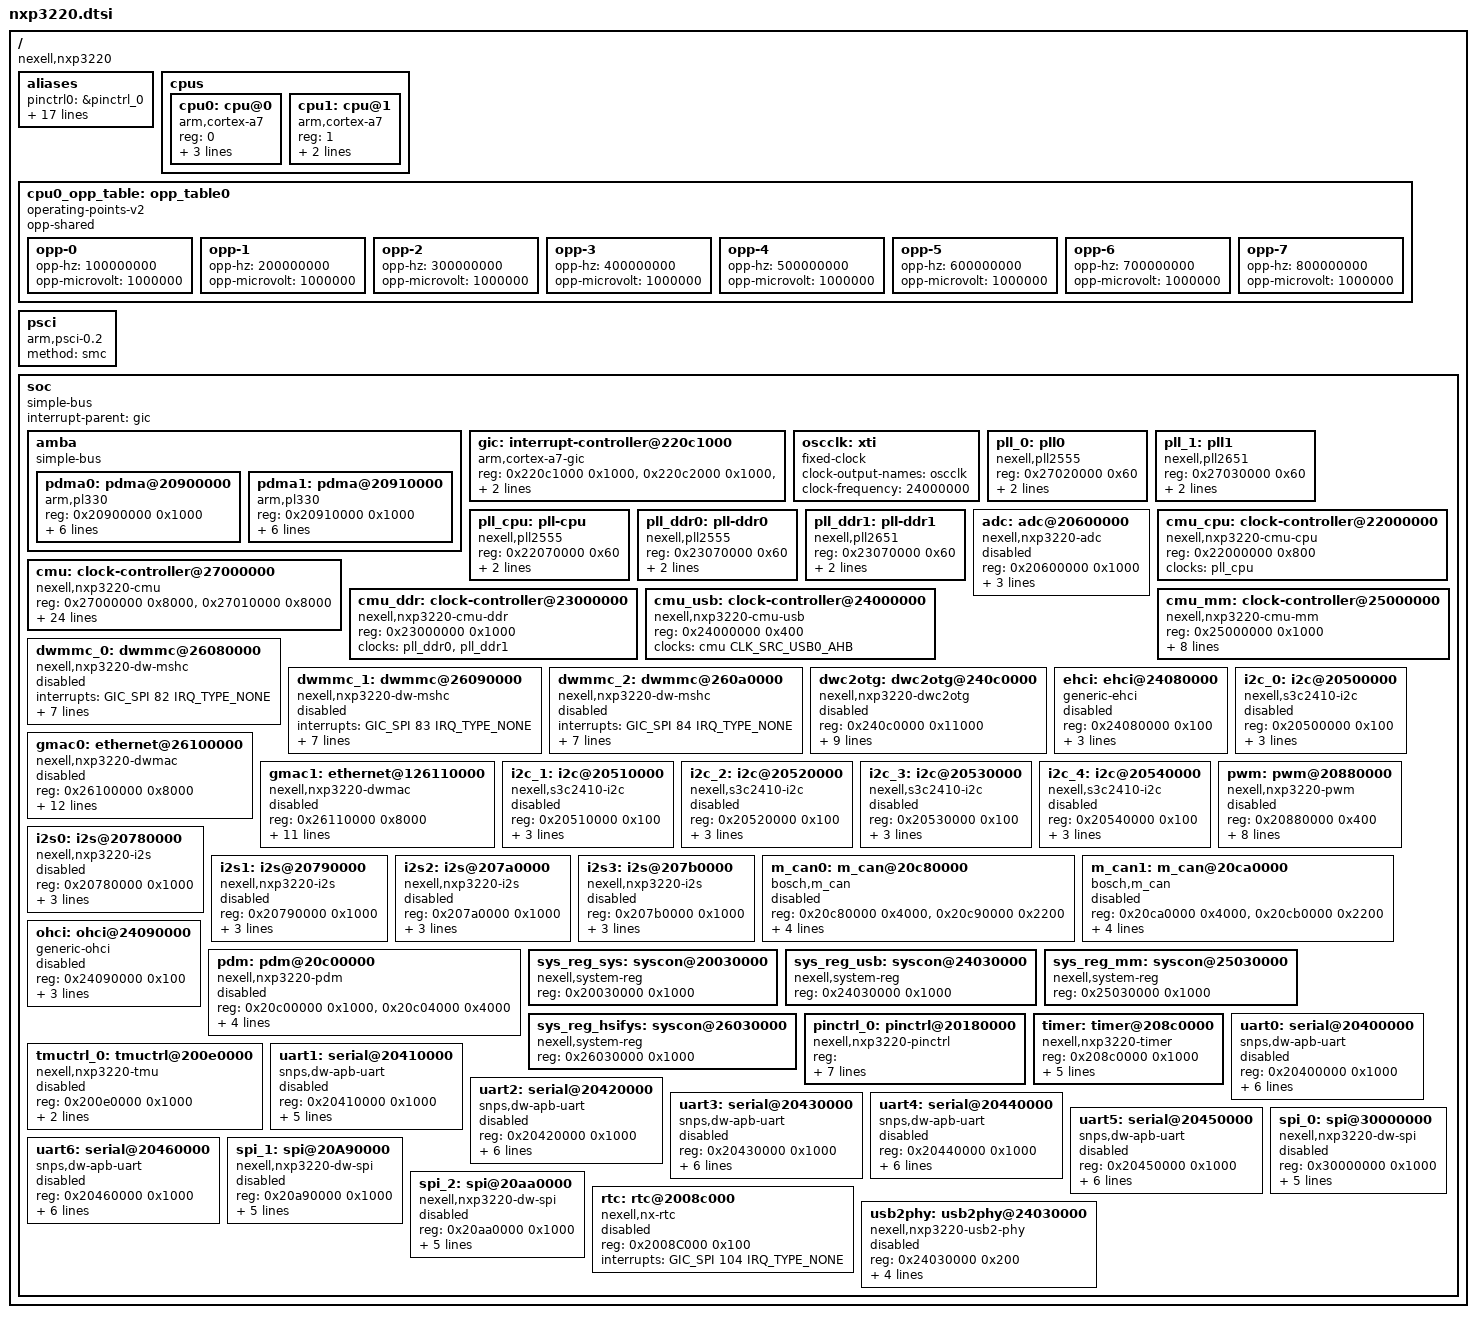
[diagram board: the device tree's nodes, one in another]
// SPDX-License-Identifier: (GPL-2.0+ OR MIT)

#include <dt-bindings/interrupt-controller/arm-gic.h>
#include <dt-bindings/clock/nxp3220-clk.h>

/ {
	compatible = "nexell,nxp3220";
	#address-cells = <0x1>;
	#size-cells = <0x1>;

	aliases {
		pinctrl0 = &pinctrl_0;
		serial0 = &uart0;
		serial1 = &uart1;
		serial2 = &uart2;
		serial3 = &uart3;
		serial4 = &uart4;
		serial5 = &uart5;
		serial6 = &uart6;
		i2c0 = &i2c_0;
		i2c1 = &i2c_1;
		i2c2 = &i2c_2;
		i2c3 = &i2c_3;
		i2c4 = &i2c_4;
		spi0 = &spi_0;
		spi1 = &spi_1;
		spi2 = &spi_2;
		ethernet0 = &gmac0;
		ethernet1 = &gmac1;
	};

	cpus {
		#address-cells = <1>;
		#size-cells = <0>;

		cpu0: cpu@0 {
			device_type = "cpu";
			compatible = "arm,cortex-a7";
			reg = <0>;
			clocks = <&cmu_cpu CLK_CPU_DIV_PLL>;
			clock-names = "cpu";
			clock-frequency = <800000000>;
			operating-points-v2 = <&cpu0_opp_table>;
			#cooling-cells = <2>;
		};

		cpu1: cpu@1 {
			device_type = "cpu";
			compatible = "arm,cortex-a7";
			reg = <1>;
			clock-frequency = <800000000>;
			operating-points-v2 = <&cpu0_opp_table>;
		};
	};

	cpu0_opp_table: opp_table0 {
		compatible = "operating-points-v2";
		opp-shared;

		opp-0 {
			opp-hz = /bits/ 64 <100000000>;
			opp-microvolt = <1000000>;
		};
		opp-1 {
			opp-hz = /bits/ 64 <200000000>;
			opp-microvolt = <1000000>;
		};
		opp-2 {
			opp-hz = /bits/ 64 <300000000>;
			opp-microvolt = <1000000>;
		};
		opp-3 {
			opp-hz = /bits/ 64 <400000000>;
			opp-microvolt = <1000000>;
		};
		opp-4 {
			opp-hz = /bits/ 64 <500000000>;
			opp-microvolt = <1000000>;
		};
		opp-5 {
			opp-hz = /bits/ 64 <600000000>;
			opp-microvolt = <1000000>;
		};
		opp-6 {
			opp-hz = /bits/ 64 <700000000>;
			opp-microvolt = <1000000>;
		};
		opp-7 {
			opp-hz = /bits/ 64 <800000000>;
			opp-microvolt = <1000000>;
		};
	};

	psci {
		compatible = "arm,psci-0.2";
		method = "smc";
	};

	soc: soc {
		compatible = "simple-bus";
		#address-cells = <1>;
		#size-cells = <1>;
		interrupt-parent = <&gic>;
		ranges;

		amba {
			#address-cells = <1>;
			#size-cells = <1>;
			compatible = "simple-bus";
			ranges;

			pdma0: pdma@20900000 {
				compatible = "arm,pl330", "arm,primecell";
				reg = <0x20900000 0x1000>;
				clocks = <&cmu CLK_DMA0_APB>,
				         <&cmu CLK_DMA0_AXI>,
				         <&cmu CLK_DMA_BUS0_AXI>;
				clock-names = "apb_pclk", "axi_clk", "axi_bclk";
				interrupts = <GIC_SPI 35 IRQ_TYPE_NONE>, <GIC_SPI 34 IRQ_TYPE_NONE>;
				#dma-cells = <1>;
				dma-channels = <8>;
				dma-requests = <32>;
			};

			pdma1: pdma@20910000 {
				compatible = "arm,pl330", "arm,primecell";
				reg = <0x20910000 0x1000>;
				clocks = <&cmu CLK_DMA1_APB>,
				         <&cmu CLK_DMA1_AXI>,
				         <&cmu CLK_DMA_BUS0_AXI>;
				clock-names = "apb_pclk", "axi_clk", "axi_bclk";
				interrupts = <GIC_SPI 37 IRQ_TYPE_NONE>, <GIC_SPI 36 IRQ_TYPE_NONE>;
				#dma-cells = <1>;
				dma-channels = <8>;
				dma-requests = <32>;
			};
		};

		gic: interrupt-controller@220c1000 {
			compatible = "arm,cortex-a7-gic";
			reg = <0x220c1000 0x1000>,
			      <0x220c2000 0x1000>,
			      <0x220c4000 0x2000>,
			      <0x220c6000 0x2000>;
			interrupt-controller;
			#interrupt-cells = <3>;
		};

		oscclk: xti {
			compatible = "fixed-clock";
			#clock-cells = <0>;
			clock-output-names = "oscclk";
			clock-frequency =  <24000000>;
		};

		pll_0: pll0 {
			compatible = "nexell,pll2555", "syscon";
			reg = <0x27020000 0x60>;

			#clock-cells = <1>;
			clocks = <&oscclk>;
			clock-output-names = "pll0";
		};

		pll_1: pll1 {
			compatible = "nexell,pll2651", "syscon";
			reg = <0x27030000 0x60>;

			#clock-cells = <1>;
			clocks = <&oscclk>;
			clock-output-names = "pll1";
		};

		pll_cpu: pll-cpu {
			compatible = "nexell,pll2555", "syscon";
			reg = <0x22070000 0x60>;

			#clock-cells = <1>;
			clocks = <&oscclk>;
			clock-output-names = "pll_cpu";
		};

		pll_ddr0: pll-ddr0 {
			compatible = "nexell,pll2555", "syscon";
			reg = <0x23070000 0x60>;

			#clock-cells = <1>;
			clocks = <&oscclk>;
			clock-output-names = "pll_ddr0";
		};

		pll_ddr1: pll-ddr1 {
			compatible = "nexell,pll2651", "syscon";
			reg = <0x23070000 0x60>;

			#clock-cells = <1>;
			clocks = <&oscclk>;
			clock-output-names = "pll_ddr1";
		};

		adc: adc@20600000 {
			compatible = "nexell,nxp3220-adc";
			reg = <0x20600000 0x1000>;
			interrupts = <GIC_SPI 0 IRQ_TYPE_NONE>;
			clocks = <&cmu CLK_ADC0_APB>;
			clock-names = "adc";
			sample_rate = <200000>;
			#io-channel-cells = <1>;
			status = "disabled";
		};

		cmu: clock-controller@27000000 {
			compatible = "nexell,nxp3220-cmu";
			reg = <0x27000000 0x8000>,
			    <0x27010000 0x8000>;
			#clock-cells = <1>;
			#reset-cells = <1>;

			clock-names = "oscclk",
				"pll0",
				"pll1",
				"div_cpu_pll",
				"div_pll_ddr0",
				"div_pll_ddr1";
			clocks = <&oscclk>,
			       <&pll_0>,
			       <&pll_1>,
			       <&cmu_cpu CLK_CPU_DIV_PLL>,
			       <&cmu_ddr CLK_DDR_DIV_PLL_DDR0>,
			       <&cmu_ddr CLK_DDR_DIV_PLL_DDR1>;

			assigned-clocks = <&pll_0 0>,
					  <&cmu CLK_SRC_TIMER0_TCLK0>,
					  <&cmu CLK_SRC_TIMER0_TCLK1>,
					  <&cmu CLK_SRC_SDMMC0_CORE>,
					  <&cmu CLK_SRC_SDMMC1_CORE>,
					  <&cmu CLK_SRC_SDMMC2_CORE>,
					  <&cmu CLK_SRC_I2C0_APB>,
					  <&cmu CLK_SRC_USB0_AHB>,
					  <&cmu CLK_SRC_GMAC_RGMII0_PTP_REF>,
					  <&cmu CLK_SRC_GMAC_RGMII0_TX>,
					  <&cmu CLK_SRC_GMAC_RMII0_PTP_REF>,
					  <&cmu CLK_SYS_DIV_SYS0_HSIF_APB>,
					  <&cmu CLK_SYS_DIV_SYS0_HSIF_AXI>,
					  <&cmu CLK_SYS_DIV_I2C0_APB>;
			assigned-clock-parents = <0>,
						 <&pll_0 0>,
						 <&pll_0 0>,
						 <&cmu CLK_PLL1_DIV>,
						 <&pll_0 0>,
						 <&pll_0 0>,
						 <&pll_0 0>,
						 <&pll_0 0>,
						 <&pll_0 0>,
						 <&pll_0 0>,
						 <&pll_0 0>,
						 <0>,
						 <0>,
						 <0>;
			assigned-clock-rates = <1000000000>,
					       <0>,
					       <0>,
					       <400000000>,
					       <200000000>,
					       <200000000>,
					       <0>,
					       <250000000>,
					       <25000000>,
					       <125000000>,
					       <25000000>,
					       <125000000>,
					       <250000000>,
					       <100000000>;
		};

		cmu_cpu: clock-controller@22000000 {
			compatible = "nexell,nxp3220-cmu-cpu";
			reg = <0x22000000 0x800>;
			#clock-cells = <1>;

			clock-names = "pll_cpu";
			clocks = <&pll_cpu>;
		};

		cmu_ddr: clock-controller@23000000 {
			compatible = "nexell,nxp3220-cmu-ddr";
			reg = <0x23000000 0x1000>;
			#clock-cells = <1>;

			clock-names = "pll_ddr0",
				"pll_ddr1";
			clocks = <&pll_ddr0>,
			         <&pll_ddr1>;
		};

		cmu_usb: clock-controller@24000000 {
			compatible = "nexell,nxp3220-cmu-usb";
			reg = <0x24000000 0x400>;
			#clock-cells = <1>;

			clock-names = "src_usb0_ahb";
			clocks = <&cmu CLK_SRC_USB0_AHB>;
		};

		cmu_mm: clock-controller@25000000 {
			compatible = "nexell,nxp3220-cmu-mm";
			reg = <0x25000000 0x1000>;
			#clock-cells = <1>;
			#reset-cells = <1>;

			clk-names = "src_mm0_axi",
				"src_vip0_padout0",
				"src_vip0_padout1",
				"src_dpc0_x2",
				"src_lvds0_vclk",
				"src_coda960_0_core";
			clocks = <&cmu CLK_SRC_MM0_AXI>,
			       <&cmu CLK_SRC_VIP0_PADOUT0>,
			       <&cmu CLK_SRC_VIP0_PADOUT1>,
			       <&cmu CLK_SRC_DPC0_X2>,
			       <&cmu CLK_SRC_LVDS0_VCLK>,
			       <&cmu CLK_SRC_CODA960_0_CORE>;
		};

		dwmmc_0: dwmmc@26080000 {
			compatible = "nexell,nxp3220-dw-mshc";
			interrupts = <GIC_SPI 82 IRQ_TYPE_NONE>;
			#address-cells = <1>;
			#size-cells = <0>;
			reg = <0x26080000 0x1000>;
			clock-frequency = <400000000>;
			clock-names = "biu", "ciu";
			clocks = <&cmu CLK_SDMMC0_AHB>,
			         <&cmu CLK_SDMMC0_CORE>;
			bus-width = <8>;
			pinctrl-names = "default";
			pinctrl-0 = <&mmc0_clk &mmc0_cmd &mmc0_bus8>;
			fifo-depth = <0x20>;
			status = "disabled";
		};

		dwmmc_1: dwmmc@26090000 {
			compatible = "nexell,nxp3220-dw-mshc";
			interrupts = <GIC_SPI 83 IRQ_TYPE_NONE>;
			#address-cells = <1>;
			#size-cells = <0>;
			reg = <0x26090000 0x1000>;
			clock-frequency = <200000000>;
			clock-names = "biu", "ciu";
			clocks = <&cmu CLK_SDMMC1_AHB>,
			         <&cmu CLK_SDMMC1_CORE>;
			bus-width = <4>;
			pinctrl-names = "default";
			pinctrl-0 = <&mmc1_clk &mmc1_cmd &mmc1_bus4>;
			fifo-depth = <0x20>;
			status = "disabled";
		};

		dwmmc_2: dwmmc@260a0000 {
			compatible = "nexell,nxp3220-dw-mshc";
			interrupts = <GIC_SPI 84 IRQ_TYPE_NONE>;
			#address-cells = <1>;
			#size-cells = <0>;
			reg = <0x260a0000 0x1000>;
			clock-frequency = <200000000>;
			clock-names = "biu","ciu";
			clocks = <&cmu CLK_SDMMC2_AHB>,
			         <&cmu CLK_SDMMC2_CORE>;
			fifo-depth = <0x20>;
			bus-width = <4>;
			pinctrl-names = "default";
			pinctrl-0 = <&mmc2_clk &mmc2_cmd &mmc2_bus4>;
			status = "disabled";
		};

		dwc2otg: dwc2otg@240c0000 {
			compatible = "nexell,nxp3220-dwc2otg";
			reg = <0x240c0000 0x11000>;
			interrupts = <GIC_SPI 123 IRQ_TYPE_NONE>;
			clocks = <&cmu_usb CLK_USB_USB20OTG>;
			clock-names = "otg";
			phys = <&usb2phy 0>;
			phy-names = "usb2-phy";
			dr_mode = "otg";
			g-use-dma = <1>;
			g-rx-fifo-size = <1064>;
			g-np-tx-fifo-size = <512>;
			g-tx-fifo-size = <512 512 512 512 256 256 256 256 256
				256 64 64 64 64 64>;
			status = "disabled";
		};

		ehci: ehci@24080000 {
			compatible = "generic-ehci";
			reg = <0x24080000 0x100>;
			interrupts = <GIC_SPI 120 IRQ_TYPE_NONE>;
			clocks = <&cmu_usb CLK_USB_USB20HOST>;
			phys = <&usb2phy 1>, <&usb2phy 2>;
			phy-names = "usb0", "usb1";
			status = "disabled";
		};

		gmac0: ethernet@26100000 {
			compatible = "nexell,nxp3220-dwmac";
			reg = <0x26100000 0x8000>;
			interrupts = <GIC_SPI 39 IRQ_TYPE_NONE>;
			interrupt-names = "macirq0";
			clocks = <&cmu CLK_GMAC_RGMII0_AXI>,
				 <&cmu CLK_GMAC_RGMII0_APB>,
				 <&cmu CLK_GMAC_RGMII0_TX>,
				 <&cmu CLK_GMAC_RGMII0_PTP_REF>;
			clock-names = "master_bus", "slave_bus", "tx", "ptp_ref";
			status = "disabled";

			snps,write-requests = <8>;
			snps,read-requests = <8>;
			snps,burst-map = <0x4>;
			snps,txpbl = <16>;
			snps,rxpbl = <16>;
			snps,no-pbl-x8;
			snps,fixed-burst;
		};

		gmac1: ethernet@126110000 {
			compatible = "nexell,nxp3220-dwmac";
			reg = <0x26110000 0x8000>;
			interrupts = <GIC_SPI 42 IRQ_TYPE_NONE>;
			interrupt-names = "macirq1";
			clocks = <&cmu CLK_GMAC_RMII0_AXI>,
				 <&cmu CLK_GMAC_RMII0_APB>,
				 <&cmu CLK_GMAC_RMII0_PTP_REF>;
			clock-names = "master_bus", "slave_bus", "ptp_ref";
			status = "disabled";

			snps,write-requests = <8>;
			snps,read-requests = <8>;
			snps,burst-map = <0x4>;
			snps,txpbl = <16>;
			snps,rxpbl = <16>;
			snps,no-pbl-x8;
			snps,fixed-burst;
		};

		i2c_0: i2c@20500000 {
			compatible = "nexell,s3c2410-i2c";
			reg = <0x20500000 0x100>;
			interrupts = <GIC_SPI 52 IRQ_TYPE_NONE>;
			clock-names = "i2c";
			clocks = <&cmu CLK_I2C0_APB>;
			pinctrl-names = "default";
			pinctrl-0 = <&i2c0_bus>;
			status = "disabled";
		};

		i2c_1: i2c@20510000 {
			compatible = "nexell,s3c2410-i2c";
			reg = <0x20510000 0x100>;
			interrupts = <GIC_SPI 53 IRQ_TYPE_NONE>;
			clock-names = "i2c";
			clocks = <&cmu CLK_I2C1_APB>;
			pinctrl-names = "default";
			pinctrl-0 = <&i2c1_bus>;
			status = "disabled";
		};

		i2c_2: i2c@20520000 {
			compatible = "nexell,s3c2410-i2c";
			reg = <0x20520000 0x100>;
			interrupts = <GIC_SPI 54 IRQ_TYPE_NONE>;
			clock-names = "i2c";
			clocks = <&cmu CLK_I2C2_APB>;
			pinctrl-names = "default";
			pinctrl-0 = <&i2c2_bus>;
			status = "disabled";
		};

		i2c_3: i2c@20530000 {
			compatible = "nexell,s3c2410-i2c";
			reg = <0x20530000 0x100>;
			interrupts = <GIC_SPI 55 IRQ_TYPE_NONE>;
			clock-names = "i2c";
			clocks = <&cmu CLK_I2C3_APB>;
			pinctrl-names = "default";
			pinctrl-0 = <&i2c3_bus>;
			status = "disabled";
		};

		i2c_4: i2c@20540000 {
			compatible = "nexell,s3c2410-i2c";
			reg = <0x20540000 0x100>;
			interrupts = <GIC_SPI 56 IRQ_TYPE_NONE>;
			clock-names = "i2c";
			clocks = <&cmu CLK_I2C4_APB>;
			pinctrl-names = "default";
			pinctrl-0 = <&i2c4_bus>;
			status = "disabled";
		};

		pwm: pwm@20880000 {
			compatible = "nexell,nxp3220-pwm";
			reg = <0x20880000 0x400>;
			clocks = <&cmu CLK_PWM0_APB>,
				 <&cmu CLK_PWM0_TCLK0>,
				 <&cmu CLK_PWM0_TCLK1>,
				 <&cmu CLK_PWM0_TCLK2>,
				 <&cmu CLK_PWM0_TCLK3>;
			clock-names = "pwm_apb", "pwm_tclk0", "pwm_tclk1",
				      "pwm_tclk2", "pwm_tclk3";
			nexell,pwm-outputs = <0>, <1>, <2>, <3>;
			tclk_freq = <100000000>, <100000000>, <100000000>, <100000000>;
			pinctrl-names = "default";
			pinctrl-0 = <&pwm0_pin &pwm1_pin &pwm2_pin &pwm3_pin>;
			status = "disabled";
		};

		i2s0: i2s@20780000 {
			compatible = "nexell,nxp3220-i2s";
			#sound-dai-cells = <0>;
			reg = <0x20780000 0x1000>;
			clocks = <&cmu CLK_I2S0_CORE>, <&cmu CLK_I2S0_APB>;
			clock-names = "i2s", "pclk";
			dmas = <&pdma0 5 &pdma0 4>;
			dma-names = "tx", "rx";
			pinctrl-names = "default";
			pinctrl-0 = <&i2s0_bus>;
			status = "disabled";
		};

		i2s1: i2s@20790000 {
			compatible = "nexell,nxp3220-i2s";
			#sound-dai-cells = <0>;
			reg = <0x20790000 0x1000>;
			clocks = <&cmu CLK_I2S1_CORE>, <&cmu CLK_I2S1_APB>;
			clock-names = "i2s", "pclk";
			dmas = <&pdma1 5 &pdma1 4>;
			dma-names = "tx", "rx";
			pinctrl-names = "default";
			pinctrl-0 = <&i2s1_bus>;
			status = "disabled";
		};

		i2s2: i2s@207a0000 {
			compatible = "nexell,nxp3220-i2s";
			#sound-dai-cells = <0>;
			reg = <0x207a0000 0x1000>;
			clocks = <&cmu CLK_I2S2_CORE>, <&cmu CLK_I2S2_APB>;
			clock-names = "i2s", "pclk";
			dmas = <&pdma0 7 &pdma0 6>;
			dma-names = "tx", "rx";
			pinctrl-names = "default";
			pinctrl-0 = <&i2s2_bus>;
			status = "disabled";
		};

		i2s3: i2s@207b0000 {
			compatible = "nexell,nxp3220-i2s";
			#sound-dai-cells = <0>;
			reg = <0x207b0000 0x1000>;
			clocks = <&cmu CLK_I2S3_CORE>, <&cmu CLK_I2S3_APB>;
			clock-names = "i2s", "pclk";
			dmas = <&pdma1 7 &pdma1 6>;
			dma-names = "tx", "rx";
			pinctrl-names = "default";
			pinctrl-0 = <&i2s3_bus>;
			status = "disabled";
		};

		m_can0: m_can@20c80000 {
			compatible = "bosch,m_can";
			reg = <0x20c80000 0x4000>, <0x20c90000 0x2200>;
			reg-names = "m_can", "message_ram";
			interrupts = <GIC_SPI 27 IRQ_TYPE_NONE>;
			interrupt-names = "int0";
			clocks = <&cmu CLK_CAN0_APB>, <&cmu CLK_CAN0_CORE>;
			clock-names = "hclk", "cclk";
			pinctrl-names = "default";
			pinctrl-0 = <&mcan0_bus>;
			bosch,mram-cfg = <0x0 0 0 64 0 0 32 32>;
			status = "disabled";
		};

		m_can1: m_can@20ca0000 {
			compatible = "bosch,m_can";
			reg = <0x20ca0000 0x4000>, <0x20cb0000 0x2200>;
			reg-names = "m_can", "message_ram";
			interrupts = <GIC_SPI 29 IRQ_TYPE_NONE>;
			interrupt-names = "int0";
			clocks = <&cmu CLK_CAN1_APB>, <&cmu CLK_CAN1_CORE>;
			clock-names = "hclk", "cclk";
			pinctrl-names = "default";
			pinctrl-0 = <&mcan1_bus>;
			bosch,mram-cfg = <0x0 0 0 64 0 0 32 32>;
			status = "disabled";
		};

		ohci: ohci@24090000 {
			compatible = "generic-ohci";
			reg = <0x24090000 0x100>;
			interrupts = <GIC_SPI 122 IRQ_TYPE_NONE>;
			clocks = <&cmu_usb CLK_USB_USB20HOST>;
			phys = <&usb2phy 1>, <&usb2phy 2>;
			phy-names = "usb0", "usb1";
			status = "disabled";
		};

		pdm: pdm@20c00000 {
			compatible = "nexell,nxp3220-pdm";
			#sound-dai-cells = <0>;
			reg = <0x20c00000 0x1000>, <0x20c04000 0x4000>;
			reg-names = "pdm", "sram";
			clocks = <&cmu CLK_PDM0_AXI>,
			       <&cmu CLK_PDM0_CORE>;
			clock-names = "axi", "core";
			interrupts = <GIC_SPI 67 IRQ_TYPE_NONE>;
			pinctrl-names = "default";
			pinctrl-0 = <&pdm_strobe>, <&pdm_lr0>, <&pdm_lr1>;
			syscon = <&sys_reg_sys>;
			status = "disabled";
		};

		sys_reg_sys: syscon@20030000 {
			compatible = "nexell,system-reg", "syscon",
				     "simple-mfd";
			reg = <0x20030000 0x1000>;
		};

		sys_reg_usb: syscon@24030000 {
			compatible = "nexell,system-reg","syscon",
				     "simple-mfd";
			reg = <0x24030000 0x1000>;
		};

		sys_reg_mm: syscon@25030000 {
			compatible = "nexell,system-reg","syscon",
				     "simple-mfd";
			reg = <0x25030000 0x1000>;
		};

		sys_reg_hsifys: syscon@26030000 {
			compatible = "nexell,system-reg","syscon",
				     "simple-mfd";
			reg = <0x26030000 0x1000>;
		};

		pinctrl_0: pinctrl@20180000 {
			compatible = "nexell,nxp3220-pinctrl";
			reg = <0x20180000 0x1000
				0x20190000 0x1000
				0x201a0000 0x1000
				0x201b0000 0x1000
				0x201c0000 0x1000
				0x2008c400 0x1c00>;
			#address-cells = <1>;
			#size-cells = <1>;
			interrupts = <GIC_SPI 45 IRQ_TYPE_NONE>,
				     <GIC_SPI 46 IRQ_TYPE_NONE>,
				     <GIC_SPI 47 IRQ_TYPE_NONE>,
				     <GIC_SPI 48 IRQ_TYPE_NONE>,
				     <GIC_SPI 49 IRQ_TYPE_NONE>,
				     <GIC_SPI 101 IRQ_TYPE_NONE>;
		};

		timer: timer@208c0000 {
			compatible = "nexell,nxp3220-timer";
			reg = <0x208c0000 0x1000>;
			clocks =  <&cmu CLK_TIMER0_TCLK0>,
			       <&cmu CLK_TIMER0_TCLK1>;
			clock-names = "timer0", "timer1";
			interrupts = <GIC_SPI 107 IRQ_TYPE_NONE>;
			clksource = <0>;
			clkevent = <1>;
		};

		tmuctrl_0: tmuctrl@200e0000 {
			compatible = "nexell,nxp3220-tmu";
			reg = <0x200e0000 0x1000>;
			interrupts = <GIC_SPI 110 IRQ_TYPE_NONE>;
			clocks = <&cmu  CLK_TMU0_APB>;
			clock-names = "tmu_apbif";
			#include "nxp3220-tmu-sensor-conf.dtsi"
			status = "disabled";
		};

		uart0: serial@20400000 {
			compatible = "snps,dw-apb-uart";
			reg = <0x20400000 0x1000>;
			interrupts = <GIC_SPI 112 IRQ_TYPE_NONE>;
			reg-shift = <2>;
			reg-io-width = <4>;
			clocks = <&cmu CLK_UART0_CORE>,
				 <&cmu CLK_UART0_APB>;
			clock-names = "baudclk", "apb_pclk";
			clock-frequency =  <100000000>;
			pinctrl-names = "default";
			pinctrl-0 = <&uart0_bus>;
			status = "disabled";
		};

		uart1: serial@20410000 {
			compatible = "snps,dw-apb-uart";
			reg = <0x20410000 0x1000>;
			interrupts = <GIC_SPI 113 IRQ_TYPE_NONE>;
			reg-shift = <2>;
			reg-io-width = <4>;
			clocks = <&cmu CLK_UART1_CORE>,
				 <&cmu CLK_UART1_APB>;
			clock-names = "baudclk", "apb_pclk";
			pinctrl-names = "default";
			pinctrl-0 = <&uart1_bus>;
			status = "disabled";
		};

		uart2: serial@20420000 {
			compatible = "snps,dw-apb-uart";
			reg = <0x20420000 0x1000>;
			interrupts = <GIC_SPI 114 IRQ_TYPE_NONE>;
			reg-shift = <2>;
			reg-io-width = <4>;
			clocks = <&cmu CLK_UART2_CORE>,
				 <&cmu CLK_UART2_APB>;
			clock-names = "baudclk", "apb_pclk";
			clock-frequency =  <100000000>;
			pinctrl-names = "default";
			pinctrl-0 = <&uart2_bus>;
			status = "disabled";
		};

		uart3: serial@20430000 {
			compatible = "snps,dw-apb-uart";
			reg = <0x20430000 0x1000>;
			interrupts = <GIC_SPI 115 IRQ_TYPE_NONE>;
			reg-shift = <2>;
			reg-io-width = <4>;
			clocks = <&cmu CLK_UART3_CORE>,
				 <&cmu CLK_UART3_APB>;
			clock-names = "baudclk", "apb_pclk";
			clock-frequency =  <100000000>;
			pinctrl-names = "default";
			pinctrl-0 = <&uart3_bus>;
			status = "disabled";
		};

		uart4: serial@20440000 {
			compatible = "snps,dw-apb-uart";
			reg = <0x20440000 0x1000>;
			interrupts = <GIC_SPI 116 IRQ_TYPE_NONE>;
			reg-shift = <2>;
			reg-io-width = <4>;
			clocks = <&cmu CLK_UART4_CORE>,
				 <&cmu CLK_UART4_APB>;
			clock-names = "baudclk", "apb_pclk";
			clock-frequency =  <100000000>;
			pinctrl-names = "default";
			pinctrl-0 = <&uart4_bus>;
			status = "disabled";
		};

		uart5: serial@20450000 {
			compatible = "snps,dw-apb-uart";
			reg = <0x20450000 0x1000>;
			interrupts = <GIC_SPI 117 IRQ_TYPE_NONE>;
			reg-shift = <2>;
			reg-io-width = <4>;
			clocks = <&cmu CLK_UART5_CORE>,
				 <&cmu CLK_UART5_APB>;
			clock-names = "baudclk", "apb_pclk";
			clock-frequency =  <100000000>;
			pinctrl-names = "default";
			pinctrl-0 = <&uart5_bus>;
			status = "disabled";
		};

		uart6: serial@20460000 {
			compatible = "snps,dw-apb-uart";
			reg = <0x20460000 0x1000>;
			interrupts = <GIC_SPI 118 IRQ_TYPE_NONE>;
			reg-shift = <2>;
			reg-io-width = <4>;
			clocks = <&cmu CLK_UART6_CORE>,
				 <&cmu CLK_UART6_APB>;
			clock-names = "baudclk", "apb_pclk";
			clock-frequency =  <100000000>;
			pinctrl-names = "default";
			pinctrl-0 = <&uart6_bus>;
			status = "disabled";
		};

		spi_0: spi@30000000 {
			compatible = "nexell,nxp3220-dw-spi";
			reg = <0x30000000 0x1000>;
			interrupts = <GIC_SPI 93 IRQ_TYPE_NONE>;
			clocks = <&cmu CLK_SPI0_CORE>,
				<&cmu CLK_SPI0_APB>;
			clock-names = "core", "apb";
			#address-cells = <1>;
			#size-cells = <0>;
			dmas = <&pdma0 0>, <&pdma0 1>;
			dma-names = "tx", "rx";
			num-cs = <1>;
			pinctrl-names = "default";
			pinctrl-0 = <&spi0_bus>;
			status = "disabled";
		};

		spi_1: spi@20A90000 {
			compatible = "nexell,nxp3220-dw-spi";
			reg = <0x20a90000 0x1000>;
			interrupts = <GIC_SPI 94 IRQ_TYPE_NONE>;
			clocks = <&cmu CLK_SPI1_CORE>,
				<&cmu CLK_SPI1_APB>;
			clock-names = "core", "apb";
			#address-cells = <1>;
			#size-cells = <0>;
			dmas = <&pdma1 0>, <&pdma1 1>;
			dma-names = "tx", "rx";
			num-cs = <1>;
			pinctrl-names = "default";
			pinctrl-0 = <&spi1_bus>;
			status = "disabled";
		};

		spi_2: spi@20aa0000 {
			compatible = "nexell,nxp3220-dw-spi";
			reg = <0x20aa0000 0x1000>;
			interrupts = <GIC_SPI 95 IRQ_TYPE_NONE>;
			clocks = <&cmu CLK_SPI2_CORE>,
				<&cmu CLK_SPI2_APB>;
			clock-names = "core", "apb";
			#address-cells = <1>;
			#size-cells = <0>;
			dmas = <&pdma0 2>, <&pdma0 3>;
			dma-names = "tx", "rx";
			num-cs = <1>;
			pinctrl-names = "default";
			pinctrl-0 = <&spi2_bus>;
			status = "disabled";
		};

		rtc: rtc@2008c000 {
			compatible = "nexell,nx-rtc";
			reg = <0x2008C000 0x100>;
			interrupts = <GIC_SPI 104 IRQ_TYPE_NONE>;
			status = "disabled";
		};

		usb2phy: usb2phy@24030000 {
			compatible = "nexell,nxp3220-usb2-phy";
			reg = <0x24030000 0x200>;
			#phy-cells = <1>;
			assigned-clocks = <&cmu_usb CLK_USB_AHB>;
			assigned-clock-rates = <250000000>;
			clocks = <&cmu_usb CLK_USB_AHB>, <&cmu_usb CLK_USB_SYSREG_APB>;
			clock-names = "ahb", "apb";
			status = "disabled";
		};
	};
};

#include "nxp3220-pinctrl.dtsi"
